# HDSC_HC32F460PETB register map
Vendor: HDSC; Series: ARMCM4; File version: 1.0
CPU: CM4 r0p1, little endian, MPU, FPU, 4 interrupt priority bits
Registers are 32-bit, read-write, reset 0x0 unless marked. A register's access mark holds for its fields unless they carry their own. Offsets are from the block's base; [hi:lo] are bit positions; {n}, {i} and the like mark numbered series; 'fields as' and 'values as' point back to an identical list.

## EFM
Base 0x40010400
0x00 FAPRT
  [15:0] FAPRT
0x04 FSTP
  [0] FSTP
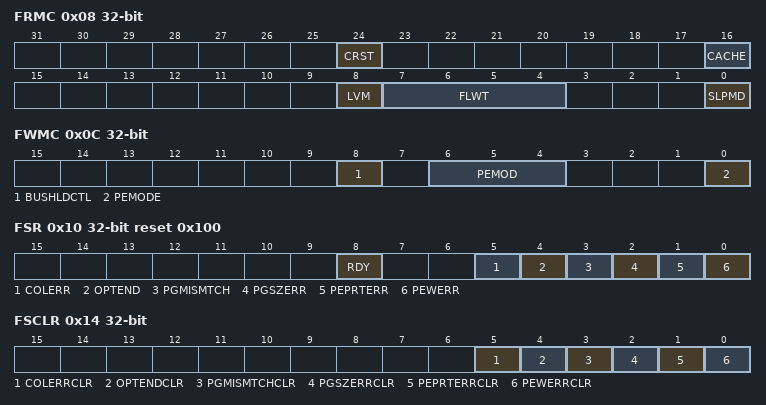
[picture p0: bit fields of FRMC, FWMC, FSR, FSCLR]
0x08 FRMC
  [24] CRST, [16] CACHE, [8] LVM, [7:4] FLWT, [0] SLPMD
0x0C FWMC
  [8] BUSHLDCTL, [6:4] PEMOD, [0] PEMODE
0x10 FSR ro reset 0x100
  [8] RDY, [5] COLERR, [4] OPTEND, [3] PGMISMTCH, [2] PGSZERR, [1] PEPRTERR, [0] PEWERR
0x14 FSCLR
  [5] COLERRCLR, [4] OPTENDCLR, [3] PGMISMTCHCLR, [2] PGSZERRCLR, [1] PEPRTERRCLR, [0] PEWERRCLR
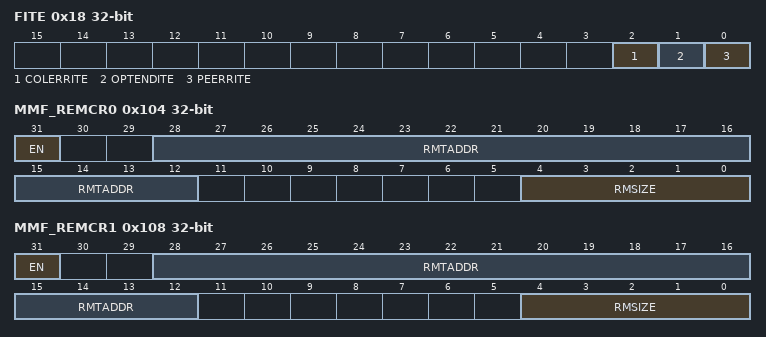
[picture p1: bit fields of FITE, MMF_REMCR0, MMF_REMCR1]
0x18 FITE
  [2] COLERRITE, [1] OPTENDITE, [0] PEERRITE
0x1C FSWP ro reset 0x1
  [0] FSWP
0x20 FPMTSW
  [18:0] FPMTSW
0x24 FPMTEW
  [18:0] FPMTEW
{0x50+4i} UQID{i} ro (i=0..2)
0x100 MMF_REMPRT
  [15:0] REMPRT
0x104 MMF_REMCR0
  [31] EN, [28:12] RMTADDR, [4:0] RMSIZE
0x108 MMF_REMCR1
  [31] EN, [28:12] RMTADDR, [4:0] RMSIZE

## EMB0 — desc EMB
Base 0x40017C00
Same registers: EMB1 0x40017C20, EMB2 0x40017C40, EMB3 0x40017C60
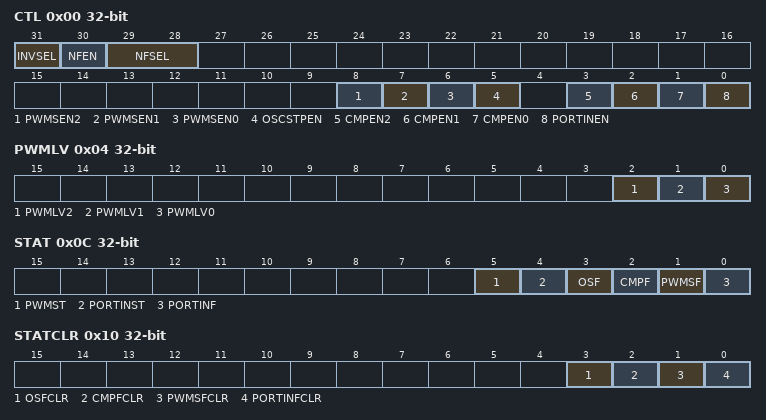
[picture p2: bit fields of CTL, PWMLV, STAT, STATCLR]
0x00 CTL
  [31] INVSEL, [30] NFEN, [29:28] NFSEL, [8] PWMSEN2, [7] PWMSEN1, [6] PWMSEN0, [5] OSCSTPEN, [3] CMPEN2, [2] CMPEN1, [1] CMPEN0, [0] PORTINEN
0x04 PWMLV
  [2] PWMLV2, [1] PWMLV1, [0] PWMLV0
0x08 SOE
  [0] SOE
0x0C STAT ro
  [5] PWMST, [4] PORTINST, [3] OSF, [2] CMPF, [1] PWMSF, [0] PORTINF
0x10 STATCLR wo
  [3] OSFCLR, [2] CMPFCLR, [1] PWMSFCLR, [0] PORTINFCLR
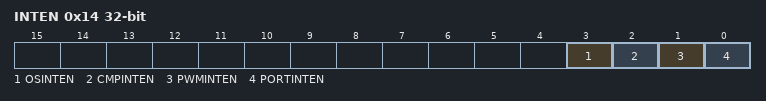
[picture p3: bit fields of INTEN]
0x14 INTEN
  [3] OSINTEN, [2] CMPINTEN, [1] PWMINTEN, [0] PORTINTEN

## FCM
Base 0x40048400
0x00 LVR
  [15:0] LVR
0x04 UVR
  [15:0] UVR
0x08 CNTR ro
  [15:0] CNTR
0x0C STR
  [0] START
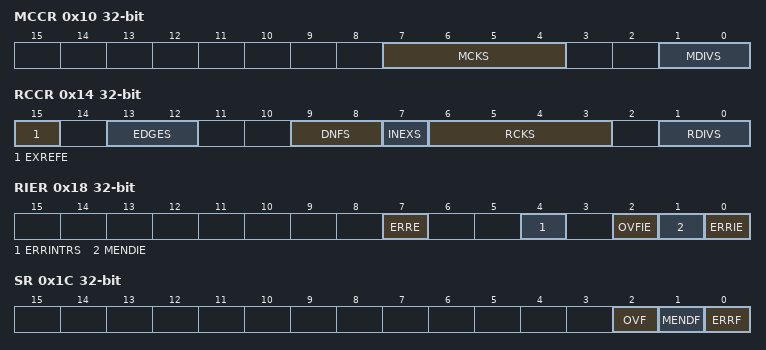
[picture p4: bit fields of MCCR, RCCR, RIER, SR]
0x10 MCCR
  [7:4] MCKS, [1:0] MDIVS
0x14 RCCR
  [15] EXREFE, [13:12] EDGES, [9:8] DNFS, [7] INEXS, [6:3] RCKS, [1:0] RDIVS
0x18 RIER
  [7] ERRE, [4] ERRINTRS, [2] OVFIE, [1] MENDIE, [0] ERRIE
0x1C SR ro
  [2] OVF, [1] MENDF, [0] ERRF
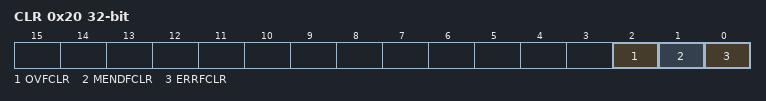
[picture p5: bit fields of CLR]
0x20 CLR wo
  [2] OVFCLR, [1] MENDFCLR, [0] ERRFCLR

## GPIO
Base 0x40053800
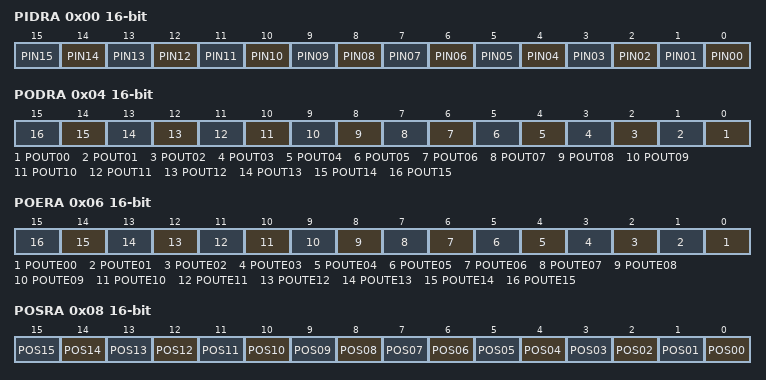
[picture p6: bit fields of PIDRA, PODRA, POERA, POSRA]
0x00 PIDRA 16-bit ro
  [n] PIN{n:02} (n=0..15)
0x04 PODRA 16-bit
  [n] POUT{n:02} (n=0..15)
0x06 POERA 16-bit
  [n] POUTE{n:02} (n=0..15)
0x08 POSRA 16-bit
  [n] POS{n:02} (n=0..15)
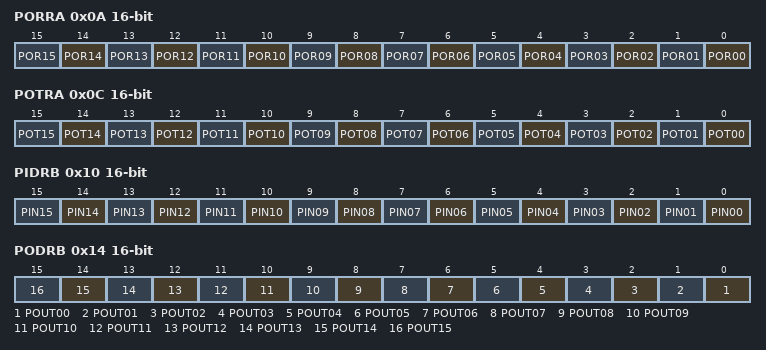
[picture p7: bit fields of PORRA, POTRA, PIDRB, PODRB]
0x0A PORRA 16-bit
  [n] POR{n:02} (n=0..15)
0x0C POTRA 16-bit
  [n] POT{n:02} (n=0..15)
0x10 PIDRB 16-bit ro
  [n] PIN{n:02} (n=0..15)
0x14 PODRB 16-bit
  [n] POUT{n:02} (n=0..15)
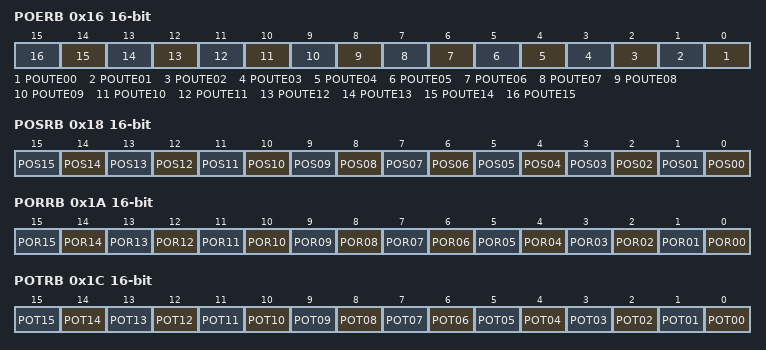
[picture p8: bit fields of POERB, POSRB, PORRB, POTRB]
0x16 POERB 16-bit
  [n] POUTE{n:02} (n=0..15)
0x18 POSRB 16-bit
  [n] POS{n:02} (n=0..15)
0x1A PORRB 16-bit
  [n] POR{n:02} (n=0..15)
0x1C POTRB 16-bit
  [n] POT{n:02} (n=0..15)
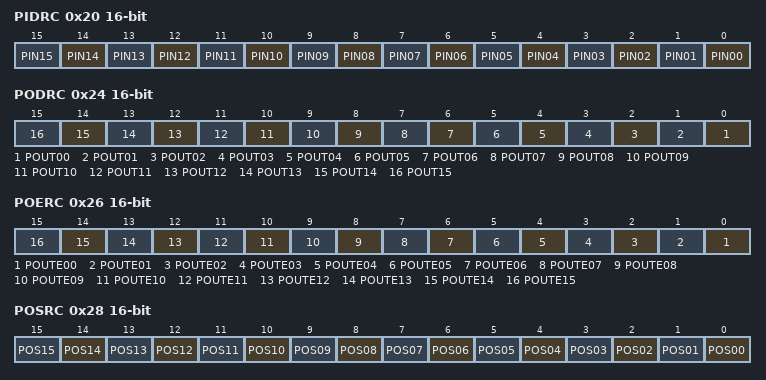
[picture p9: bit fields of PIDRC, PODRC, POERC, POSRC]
0x20 PIDRC 16-bit ro
  [n] PIN{n:02} (n=0..15)
0x24 PODRC 16-bit
  [n] POUT{n:02} (n=0..15)
0x26 POERC 16-bit
  [n] POUTE{n:02} (n=0..15)
0x28 POSRC 16-bit
  [n] POS{n:02} (n=0..15)
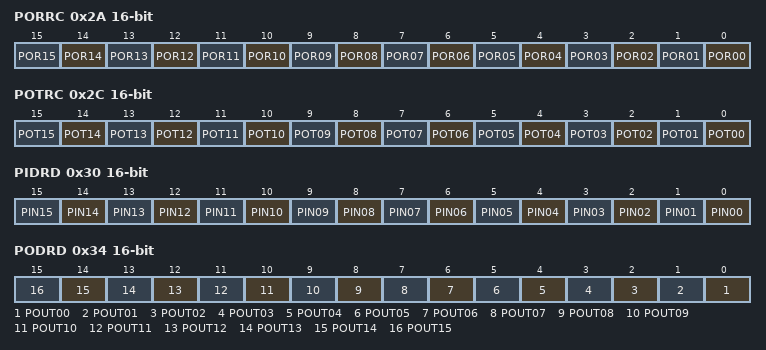
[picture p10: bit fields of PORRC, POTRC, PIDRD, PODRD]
0x2A PORRC 16-bit
  [n] POR{n:02} (n=0..15)
0x2C POTRC 16-bit
  [n] POT{n:02} (n=0..15)
0x30 PIDRD 16-bit ro
  [n] PIN{n:02} (n=0..15)
0x34 PODRD 16-bit
  [n] POUT{n:02} (n=0..15)
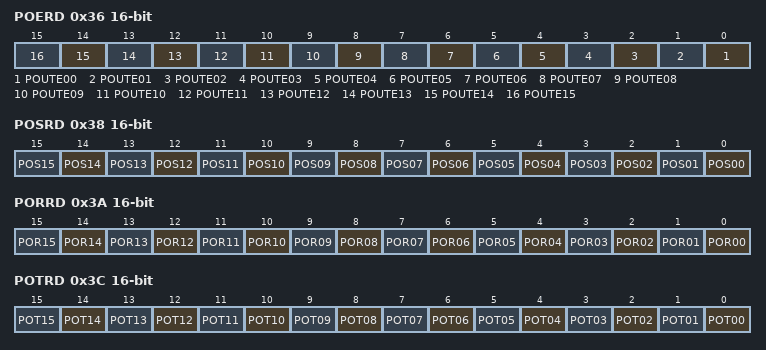
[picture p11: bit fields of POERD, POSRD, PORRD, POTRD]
0x36 POERD 16-bit
  [n] POUTE{n:02} (n=0..15)
0x38 POSRD 16-bit
  [n] POS{n:02} (n=0..15)
0x3A PORRD 16-bit
  [n] POR{n:02} (n=0..15)
0x3C POTRD 16-bit
  [n] POT{n:02} (n=0..15)
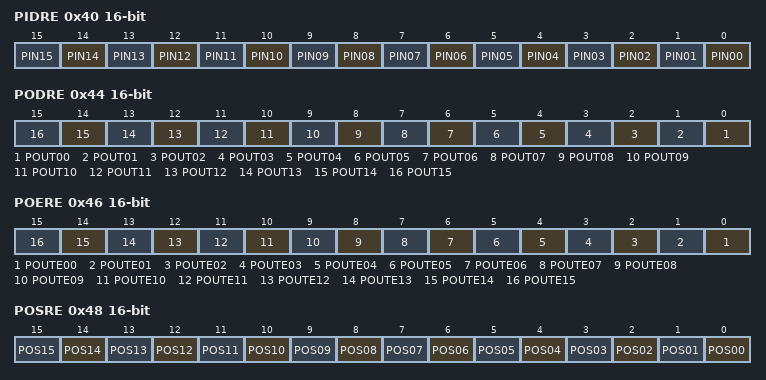
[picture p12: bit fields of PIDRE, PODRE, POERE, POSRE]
0x40 PIDRE 16-bit ro
  [n] PIN{n:02} (n=0..15)
0x44 PODRE 16-bit
  [n] POUT{n:02} (n=0..15)
0x46 POERE 16-bit
  [n] POUTE{n:02} (n=0..15)
0x48 POSRE 16-bit
  [n] POS{n:02} (n=0..15)
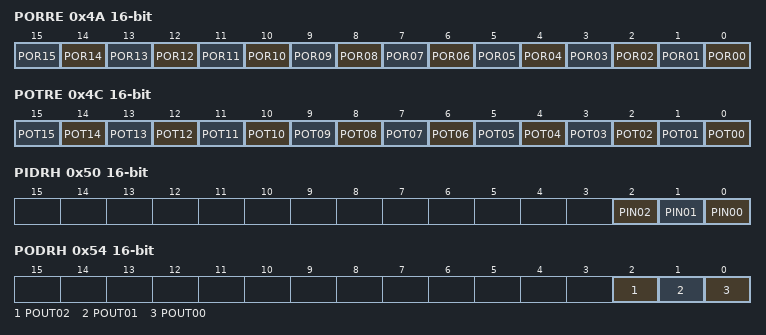
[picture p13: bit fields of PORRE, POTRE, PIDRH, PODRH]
0x4A PORRE 16-bit
  [n] POR{n:02} (n=0..15)
0x4C POTRE 16-bit
  [n] POT{n:02} (n=0..15)
0x50 PIDRH 16-bit ro
  [2] PIN02, [1] PIN01, [0] PIN00
0x54 PODRH 16-bit
  [2] POUT02, [1] POUT01, [0] POUT00
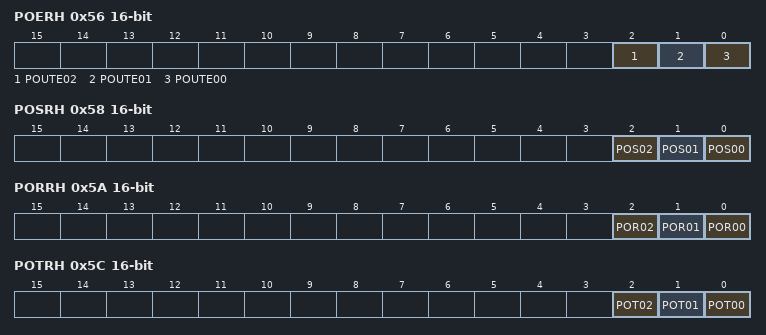
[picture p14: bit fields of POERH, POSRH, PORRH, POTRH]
0x56 POERH 16-bit
  [2] POUTE02, [1] POUTE01, [0] POUTE00
0x58 POSRH 16-bit
  [2] POS02, [1] POS01, [0] POS00
0x5A PORRH 16-bit
  [2] POR02, [1] POR01, [0] POR00
0x5C POTRH 16-bit
  [2] POT02, [1] POT01, [0] POT00
0x3F4 PSPCR 16-bit
  [4:0] SPFE
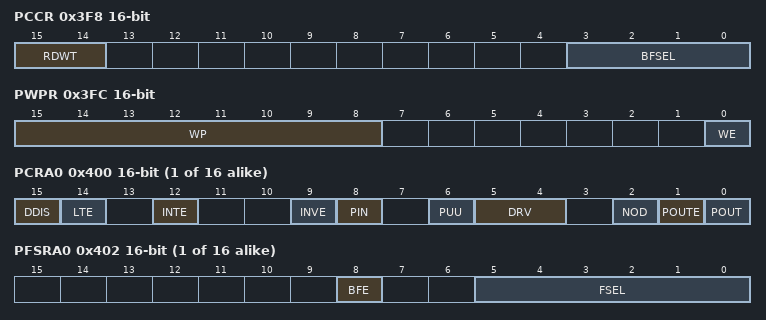
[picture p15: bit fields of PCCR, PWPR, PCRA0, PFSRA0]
0x3F8 PCCR 16-bit
  [15:14] RDWT, [3:0] BFSEL
0x3FA PINAER 16-bit
  [5:0] PINAE
0x3FC PWPR 16-bit
  [15:8] WP wo, [0] WE
{0x400+4i} PCRA{i} 16-bit (i=0..15)
  [15] DDIS, [14] LTE, [12] INTE, [9] INVE, [8] PIN ro, [6] PUU, [5:4] DRV, [2] NOD, [1] POUTE, [0] POUT
{0x402+4i} PFSRA{i} 16-bit (i=0..15)
  [8] BFE, [5:0] FSEL
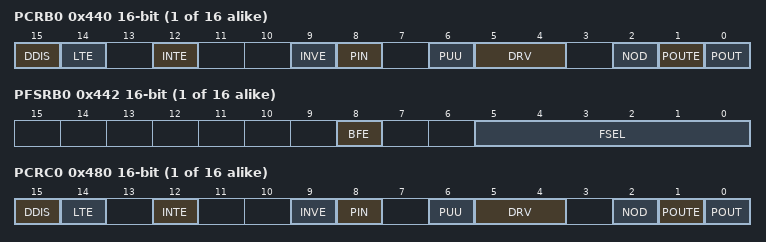
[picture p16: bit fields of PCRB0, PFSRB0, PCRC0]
{0x440+4i} PCRB{i} 16-bit (i=0..15)
  fields as PCRA0
{0x442+4i} PFSRB{i} 16-bit (i=0..15)
  [8] BFE, [5:0] FSEL
{0x480+4i} PCRC{i} 16-bit (i=0..15)
  fields as PCRA0
{0x482+4i} PFSRC{i} 16-bit (i=0..15)
  [8] BFE, [5:0] FSEL
{0x4C0+4i} PCRD{i} 16-bit (i=0..5)
  fields as PCRA0
{0x4C2+4i} PFSRD{i} 16-bit (i=0..15)
  [8] BFE, [5:0] FSEL
0x4D8 PCRD6 16-bit reset 0x8100
  fields as PCRA0
0x4DC PCRD7 16-bit reset 0x8100
  fields as PCRA0
{0x4C0+4i} PCRD{i} 16-bit (i=8..15)
  fields as PCRA0
0x500 PCRE0 16-bit
  fields as PCRA0
0x502 PFSRE0 16-bit
  [8] BFE, [5:0] FSEL
0x504 PCRE1 16-bit reset 0x40
  fields as PCRA0
0x506 PFSRE1 16-bit reset 0xD
  [8] BFE, [5:0] FSEL
{0x500+4i} PCRE{i} 16-bit (i=2..15)
  fields as PCRA0
{0x502+4i} PFSRE{i} 16-bit (i=2..15)
  [8] BFE, [5:0] FSEL
0x540 PCRH0 16-bit
  fields as PCRA0
0x542 PFSRH0 16-bit
  [8] BFE, [5:0] FSEL
0x544 PCRH1 16-bit reset 0x40
  fields as PCRA0
0x546 PFSRH1 16-bit reset 0xD
  [8] BFE, [5:0] FSEL
0x548 PCRH2 16-bit reset 0x50
  fields as PCRA0
0x54A PFSRH2 16-bit reset 0xD
  [8] BFE, [5:0] FSEL
